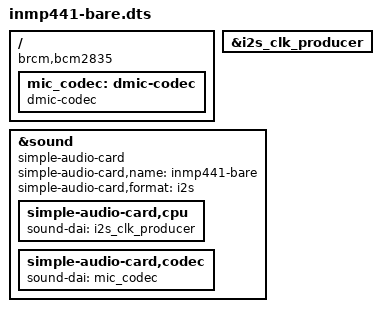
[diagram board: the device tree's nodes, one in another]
// Overlay I2S "bare" para INMP441 / micrófono I2S esclavo.
//
// Usa el codec genérico "dmic-codec" (snd-soc-dmic), el driver estándar del
// kernel para micrófonos MEMS digitales, en lugar del dummy "google,voicehat"
// (que requería un GPIO de sdmode del HAT de amplificador y expone captura y
// reproducción que aquí no se usan).
//
// Estructura idéntica a la probada-funcional de trackIT-Systems/snd-i2s_rpi
// (i2s-soundcard.dts, driver del Adafruit I2S MEMS mic) y a
// Virgil-Zu/snd-soc-inmp441: simple-audio-card con format=i2s y SIN
// bitclock/frame-master (el default es la CPU como master del reloj) y SIN
// dai-tdm-slot-num/width. Con la CPU como master, BCLK (GPIO18) y WS (GPIO19)
// se generan y el INMP441 (esclavo) entrega datos por GPIO20.
//
// IMPORTANTE: no añadir aquí dai-tdm-slot-num/width ni num-channels. La
// variante con TDM 2 slots x 32 bits + num-channels=<2> producía un BCLK
// erróneo (captura a ~3.5 kHz en vez de 48 kHz -> grabaciones silenciosas y
// más cortas de lo pedido); la estructura mínima de este archivo es la que el
// driver bcm2835-i2s clokea correctamente.
//
// Formato I2S, 2 slots x 32 bits (S32_LE, 24 bits útiles alineados al MSB).
//
// Instalación:
//   dtc -@ -I dts -O dtb -o inmp441-bare.dtbo inmp441-bare.dts
//   sudo cp inmp441-bare.dtbo /boot/firmware/overlays/
//   # en config.txt: dtoverlay=inmp441-bare[,alsaname=mems-mic]
/dts-v1/;
/plugin/;

/ {
	compatible = "brcm,bcm2835";

	fragment@0 {
		target = <&i2s_clk_producer>;
		__overlay__ {
			status = "okay";
		};
	};

	fragment@1 {
		target-path = "/";
		__overlay__ {
			mic_codec: dmic-codec {
				#sound-dai-cells = <0>;
				compatible = "dmic-codec";
				status = "okay";
			};
		};
	};

	fragment@2 {
		target = <&sound>;
		__overlay__ {
			compatible = "simple-audio-card";
			status = "okay";

			simple-audio-card,name = "inmp441-bare";
			simple-audio-card,format = "i2s";

			simple-audio-card,cpu {
				sound-dai = <&i2s_clk_producer>;
			};

			simple-audio-card,codec {
				sound-dai = <&mic_codec>;
			};
		};
	};

	__overrides__ {
		alsaname = <&sound>, "simple-audio-card.name";
	};
};
